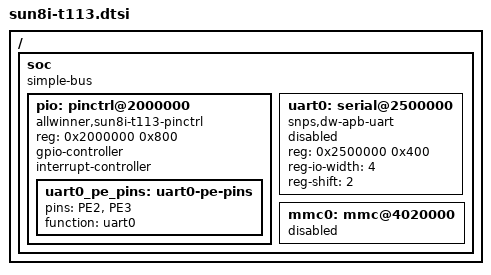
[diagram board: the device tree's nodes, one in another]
/ {
	#address-cells = <1>;
	#size-cells = <1>;

	soc {
		compatible = "simple-bus";
		#address-cells = <1>;
		#size-cells = <1>;
		ranges;

		pio: pinctrl@2000000 {
			compatible = "allwinner,sun8i-t113-pinctrl";
			reg = <0x2000000 0x800>;
			gpio-controller;
			#gpio-cells = <3>;
			interrupt-controller;
			#interrupt-cells = <3>;

			/omit-if-no-ref/
			uart0_pe_pins: uart0-pe-pins {
				pins = "PE2", "PE3";
				function = "uart0";
			};
        };

		uart0: serial@2500000 {
			compatible = "snps,dw-apb-uart";
			reg = <0x2500000 0x400>;
			reg-io-width = <4>;
			reg-shift = <2>;
			// interrupts = <GIC_SPI 2 IRQ_TYPE_LEVEL_HIGH>;
			// clocks = <&ccu CLK_BUS_UART0>;
			// resets = <&ccu RST_BUS_UART0>;
			// dmas = <&dma 14>, <&dma 14>;
			// dma-names = "rx", "tx";
			status = "disabled";
		};

        mmc0: mmc@4020000 {
            status = "disabled";
        };
	};
};
